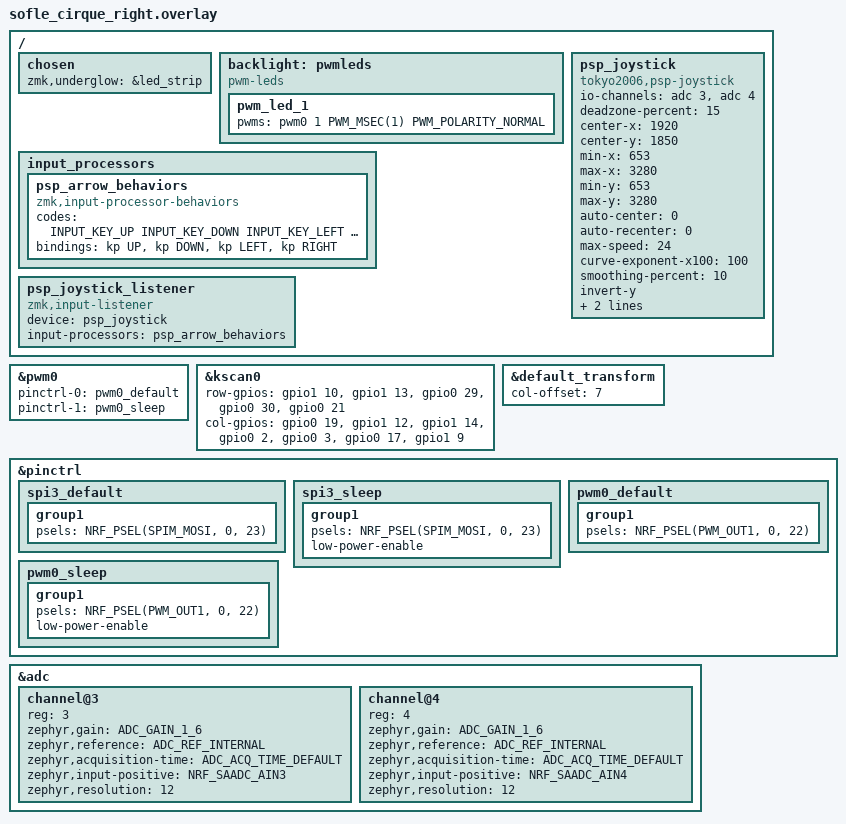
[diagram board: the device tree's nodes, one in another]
/*
 * Copyright (c) 2020 ZMK Contributors
 *
 * SPDX-License-Identifier: MIT
 */
#include <dt-bindings/zmk/input_transform.h>
#include <dt-bindings/led/led.h>
#include <zephyr/dt-bindings/adc/adc.h>
#include <zephyr/dt-bindings/adc/nrf-adc.h>
#include <zephyr/dt-bindings/input/input-event-codes.h>
#include <behaviors/battery_history_request.dtsi>
#include "sofle_cirque.dtsi"

#include "rgb.dtsi"
#include "azoteq.dtsi"

/ {
    chosen {
        zmk,underglow = &led_strip;
    };

    backlight: pwmleds {
        compatible = "pwm-leds";
        pwm_led_1: pwm_led_1 {
            pwms = <&pwm0 1 PWM_MSEC(1) PWM_POLARITY_NORMAL>;
        };
    };
};

&pwm0 {
    status = "okay";
    pinctrl-0 = <&pwm0_default>;
    pinctrl-1 = <&pwm0_sleep>;
    pinctrl-names = "default", "sleep";
};

&kscan0 {
    row-gpios
                = <&gpio1 10 (GPIO_ACTIVE_HIGH | GPIO_PULL_DOWN)>
                , <&gpio1 13 (GPIO_ACTIVE_HIGH | GPIO_PULL_DOWN)>
                , <&gpio0 29 (GPIO_ACTIVE_HIGH | GPIO_PULL_DOWN)>
                , <&gpio0 30 (GPIO_ACTIVE_HIGH | GPIO_PULL_DOWN)>
                , <&gpio0 21 (GPIO_ACTIVE_HIGH | GPIO_PULL_DOWN)>
    ;
    col-gpios
                = <&gpio0 19 (GPIO_ACTIVE_HIGH)>
                , <&gpio1 12 (GPIO_ACTIVE_HIGH)>
                , <&gpio1 14 (GPIO_ACTIVE_HIGH)>
                , <&gpio0 2 (GPIO_ACTIVE_HIGH)>
                , <&gpio0 3 (GPIO_ACTIVE_HIGH)>
                , <&gpio0 17 (GPIO_ACTIVE_HIGH)>
                , <&gpio1 9 (GPIO_ACTIVE_HIGH)>
    ;
};

&default_transform {
    col-offset = <7>;
};

&pinctrl {
    spi3_default: spi3_default {
        group1 {
            psels = <NRF_PSEL(SPIM_MOSI, 0, 23)>;
        };
    };
    spi3_sleep: spi3_sleep {
        group1 {
            psels = <NRF_PSEL(SPIM_MOSI, 0, 23)>;
            low-power-enable;
        };
    };
};

&pinctrl {
    pwm0_default: pwm0_default {
        group1 {
            psels = <NRF_PSEL(PWM_OUT1, 0, 22)>;
        };
    };
    pwm0_sleep: pwm0_sleep {
        group1 {
            psels = <NRF_PSEL(PWM_OUT1, 0, 22)>;
            low-power-enable;
        };
    };
};

/*
 * PSP joystick on the main/central (right) half.
 *
 * X = P0.05 (AIN3), Y = P0.28 (AIN4), VCC = 3.3V, GND = GND.
 *
 * The board does not break out P0.04 (AIN2) and P0.31 (AIN7), so the only
 * free SAADC pin is P0.05. To get a second analog input, matrix column 5
 * was moved from P0.28 to P0.17 (the unused OLED MOSI pad), freeing P0.28.
 * P0.28 must be cut from the matrix column trace and wired to the joystick Y.
 * P0.17 must be wired to that matrix column instead.
 */
&adc {
    status = "okay";
    #address-cells = <1>;
    #size-cells = <0>;

    channel@3 {
        reg = <3>;
        zephyr,gain = "ADC_GAIN_1_6";
        zephyr,reference = "ADC_REF_INTERNAL";
        zephyr,acquisition-time = <ADC_ACQ_TIME_DEFAULT>;
        zephyr,input-positive = <NRF_SAADC_AIN3>;
        zephyr,resolution = <12>;
    };

    channel@4 {
        reg = <4>;
        zephyr,gain = "ADC_GAIN_1_6";
        zephyr,reference = "ADC_REF_INTERNAL";
        zephyr,acquisition-time = <ADC_ACQ_TIME_DEFAULT>;
        zephyr,input-positive = <NRF_SAADC_AIN4>;
        zephyr,resolution = <12>;
    };
};

/ {
    psp_joystick: psp_joystick {
        compatible = "tokyo2006,psp-joystick";
        io-channels = <&adc 3>, <&adc 4>;
        io-channel-names = "x", "y";

        /*
         * Center is the midpoint of the left/right rest positions (1797 and
         * 2043). The stick has ~250 counts of direction-dependent rest
         * hysteresis; a 15% deadzone covers both sides. Auto-center and
         * auto-recenter are off so the center does not chase one side and
         * make the other side drift.
         */
        deadzone-percent = <15>;
        center-x = <1920>;
        center-y = <1850>;
        min-x = <653>;
        max-x = <3280>;
        min-y = <653>;
        max-y = <3280>;
        auto-center = <0>;
        auto-recenter = <0>;
        max-speed = <24>;
        curve-exponent-x100 = <100>;
        smoothing-percent = <10>;
        invert-y;
        arrow-mode = <0>;
        arrow-threshold-percent = <50>;
    };

    input_processors {
        psp_arrow_behaviors: psp_arrow_behaviors {
            compatible = "zmk,input-processor-behaviors";
            #input-processor-cells = <0>;
            codes = <INPUT_KEY_UP INPUT_KEY_DOWN INPUT_KEY_LEFT INPUT_KEY_RIGHT>;
            bindings = <&kp UP &kp DOWN &kp LEFT &kp RIGHT>;
        };
    };

    psp_joystick_listener: psp_joystick_listener {
        compatible = "zmk,input-listener";
        device = <&psp_joystick>;
        input-processors = <&psp_arrow_behaviors>;
    };
};
